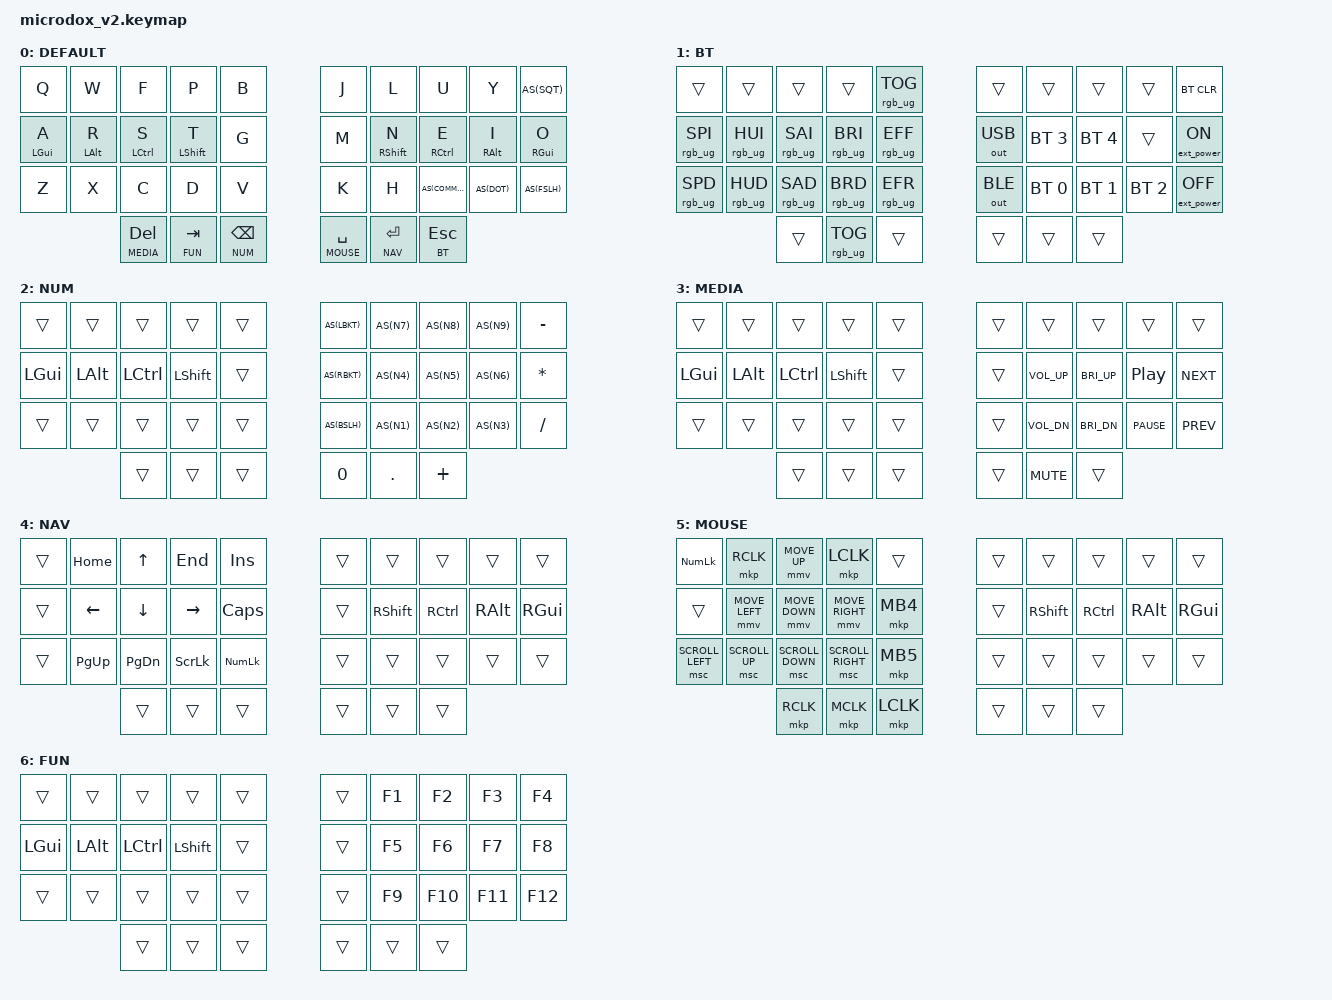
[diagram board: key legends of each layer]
/*
 * Copyright (c) 2020 The ZMK Contributors
 *
 * SPDX-License-Identifier: MIT
 */

#include <behaviors.dtsi>
#include <dt-bindings/zmk/keys.h>
#include <dt-bindings/zmk/bt.h>
#include <dt-bindings/zmk/outputs.h>
#include <dt-bindings/zmk/ext_power.h>
#include <dt-bindings/zmk/rgb.h>
#include <dt-bindings/zmk/mouse.h>

#define DEFAULT 0
#define BT      1
#define NUM     2
#define MEDIA   3
#define NAV     4
#define MOUSE   5
#define FUN     6

#define AS(keycode) &as LS(keycode) keycode

&lt { quick_tap_ms = <140>; };

&sk {
    release-after-ms = <1000>;
    quick-release;
    /delete-property/ ignore-modifiers;
};
/ {
    macros {
         ZMK_MACRO(macro_email,
            wait-ms = <20>;
            tap-ms = <20>;
            bindings
                = <&macro_tap &kp C &kp H &kp E &kp U &kp N &kp G &kp DOT &kp E &kp D &kp E &kp N &kp DOT &kp L &kp A &kp W>
                , <&macro_press &kp LSHFT>
                , <&macro_tap &kp N2>
                , <&macro_release &kp LSHFT>
                , <&macro_tap &kp G &kp M &kp A &kp I &kp L &kp DOT &kp C &kp O &kp M>
                ;
        )
    };
};

/{
    combos {
        compatible = "zmk,combos";
        combo_min {
            timeout-ms = <25>;
            key-positions = <3 13>;
            bindings = <&kp MINUS>;
        };
        
        combo_gresc {
            timeout-ms = <25>;
            key-positions = <23 24>;
            bindings = <&kp ESC>;
        };
        
        combo_caps {
            timeout-ms = <25>;
            key-positions = <13 14>;
            bindings = <&caps_word>;
        }; 
        
        combo_lpar {
            timeout-ms = <25>;
            key-positions = <3 4>;
            bindings = <&kp LPAR>;
        };
       
        combo_eql {
            timeout-ms = <25>;
            key-positions = <6 16>;
            bindings = <&kp EQUAL>;
        };
        
        combo_semi {
            timeout-ms = <20>;
            key-positions = <15 16>;
            bindings = <&kp SEMI>;
        }; 
        
        combo_rpar {
            timeout-ms = <25>;
            key-positions = <5 6>;
            bindings = <&kp RPAR>;
        };
        
        combo_print {
            timeout-ms = <25>;
            key-positions = <0 9>;
            bindings = <&kp PSCRN>;
        };        
 
         combo_play {
            timeout-ms = <25>;
            key-positions = <0 20>;
            bindings = <&kp C_PP>;
        };
        
        combo_mute {
            timeout-ms = <25>;
            key-positions = <9 29>;
            bindings = <&kp C_MUTE>;
        };     
        
        combo_del {
            timeout-ms = <25>;
            key-positions = <31 32>;
            bindings = <&kp DEL>;
        };
        
        combo_grescr {
            timeout-ms = <25>;
            key-positions = <33 34>;
            bindings = <&gresc>;
        };  
        combo_email {
            timeout-ms = <25>;
            key-positions = <25 26>;
            bindings = <&macro_email>;
        };

    };
};

/{
    behaviors {
        hm: homerow_mods {
            compatible = "zmk,behavior-hold-tap";
            label = "HOMEROW_MODS";
            #binding-cells = <2>;
            tapping-term-ms = <180>; // <---[[produces tap if held longer than tapping-term-ms]]
            quick-tap-ms = <140>;
            flavor = "tap-preferred";
            bindings = <&kp>, <&kp>;
        };
        
       as: auto_shift {
            compatible = "zmk,behavior-hold-tap";
            label = "AUTO_SHIFT";
            #binding-cells = <2>;
            tapping_term_ms = <180>;
            quick_tap_ms = <0>;
            flavor = "tap-preferred";
            bindings = <&kp>, <&kp>;
        };  
        
     gresc: grave_escape {
            compatible = "zmk,behavior-mod-morph";
            label = "GRAVE_ESCAPE";
            #binding-cells = <0>;
            bindings = <&kp ESC>, <&kp GRAVE>;
            mods = <(MOD_LGUI|MOD_LSFT|MOD_RGUI|MOD_RSFT)>;
        };   
    }; 
};

&mmv {
    time-to-max-speed-ms = <300>;
};

&mwh {
    acceleration-exponent=<0>;
};

/{
    keymap {
        compatible = "zmk,keymap";

                      DEFAULT {
// -----------------------------------------------------------------------------------------
//                              |  Q  |  W  |  F  |  P  |  B  |   |  J  |  L   |  U  |  Y  |  '  | 
//                              |  A  |  R  |  S  |  T  |  G  |   |  M  |  N   |  E  |  I  |  O  |
//                              |  Z  |  X  |  C  |  D  |  V  |   |  K  |  H   |  ,  |  .  |  /  | 
//                                          | DEL | TAB | BSP |   | SPC  | ENT | ESC |
                        bindings = <
  &kp Q      &kp W      &kp F         &kp P        &kp B         &kp J      &kp L            &kp U       &kp Y       AS(SQT)    
  &hm LGUI A &hm LALT R &hm LCTRL S   &hm LSHIFT T &kp G         &kp M      &hm RSHIFT N     &hm RCTRL E &hm RALT I  &hm RGUI O 
  &kp Z      &kp X      &kp C         &kp D        &kp V         &kp K      &kp H            AS(COMMA)   AS(DOT)     AS(FSLH)   
                     &lt MEDIA DEL  &lt FUN TAB &lt NUM BSPC  &lt MOUSE SPACE &lt NAV RET  &lt BT ESC
                        >;
                
                sensor-bindings = <&inc_dec_kp C_VOL_DN C_VOL_UP &inc_dec_kp PG_UP PG_DN>; 
                        
                };
                BT {
// -----------------------------------------------------------------------------------------
//                         |      |     |     |     |     |     |   |     |     |     |     | BTCR |
//                         | EPON |     |     |     |     |     |   |USBPR| BT4 | BT5 |     | EPON |
//                         | EPOFF|     |     |     |     |     |   |BT PR| BT1 | BT2 | BT3 | EPOFF|
//                                            |     |     |     |   |     |     |     |     
                        bindings = <
   &trans          &trans          &trans          &trans          &rgb_ug RGB_TOG    &trans        &trans        &trans       &trans        &bt BT_CLR
   &rgb_ug RGB_SPI &rgb_ug RGB_HUI &rgb_ug RGB_SAI &rgb_ug RGB_BRI &rgb_ug RGB_EFF    &out OUT_USB  &bt BT_SEL 3  &bt BT_SEL 4 &trans        &ext_power EP_ON
   &rgb_ug RGB_SPD &rgb_ug RGB_HUD &rgb_ug RGB_SAD &rgb_ug RGB_BRD &rgb_ug RGB_EFR    &out OUT_BLE  &bt BT_SEL 0  &bt BT_SEL 1 &bt BT_SEL 2  &ext_power EP_OFF
                         &trans     &rgb_ug RGB_TOG &trans             &trans        &trans        &trans
                        >;
                };

                NUM {
// -----------------------------------------------------------------------------------------
//                       |     |     |     |     |     |   |  [  |  7  |  8  |  9  |  -  | 
//                       | GUI | ALT | CTL | SFT |     |   |  ]  |  4  |  5  |  6  |  *  | 
//                       |     |     |     |     |     |   |  \  |  1  |  2  |  3  |  /  | 
//                                   |     |     |     |   |  +  |  0  |  .  |     
                        bindings = <
  &trans     &trans     &trans     &trans     &trans         AS(LBKT)   AS(N7)  AS(N8) AS(N9) &kp MINUS 
  &kp LGUI   &kp LALT   &kp LCTRL  &kp LSHFT  &trans         AS(RBKT)   AS(N4)  AS(N5) AS(N6) &kp STAR  
  &trans     &trans     &trans     &trans     &trans         AS(BSLH)   AS(N1)  AS(N2) AS(N3) &kp FSLH 
                        &trans     &trans     &trans         &kp N0     &kp DOT &kp PLUS   
                        >;
                        
                        sensor-bindings = <&inc_dec_kp C_VOL_DN C_VOL_UP>; 
                };
                
                MEDIA {
// -----------------------------------------------------------------------------------------
//                     |     |     |     |     |     |   |     |     |     |     |     |
//                     | GUI | ALT | CTL | SFT |     |   |     | VUP | BUP | PLY | NXT | 
//                     |     |     |     |     |     |   |     | VDN | BDN | PSE | PRV |
//                                 |     |     |     |   |     |     | MUTE|     |
                        bindings = <
    &trans     &trans     &trans     &trans     &trans         &trans   &trans       &trans       &trans      &trans     
    &kp LGUI   &kp LALT   &kp LCTRL  &kp LSHFT  &trans         &trans   &kp C_VOL_UP &kp C_BRI_UP &kp C_PP    &kp C_NEXT 
    &trans     &trans     &trans     &trans     &trans         &trans   &kp C_VOL_DN &kp C_BRI_DN &kp C_PAUSE &kp C_PREV 
                   	      &trans     &trans     &trans         &trans   &kp C_MUTE   &trans
                        >;
                };
                
                NAV {
// -----------------------------------------------------------------------------------------
//                           |     | HOME|  UP | END | INS |   |     |     |     |     |     |  
//                           |     | LEFT| DOWN|RIGHT| CAPS|   |     | SFT | CTL | ALT | GUI |   
//                           |     | PGUP| PGDN| SLCK| NUML|   |     |     |     |     |     | 
//                                       |     |     |     |   |     |     |     |     
                        bindings = <
   &trans    &kp HOME   &kp UP     &kp END    &kp INS        &trans   &trans     &trans     &trans     &trans    
   &trans    &kp LEFT   &kp DOWN   &kp RIGHT  &kp CAPS       &trans   &kp RSHFT  &kp RCTRL  &kp RALT   &kp RGUI 
   &trans    &kp PG_UP  &kp PG_DN  &kp SLCK   &kp KP_NUM     &trans   &trans     &trans     &trans     &trans   
                        &trans     &trans     &trans         &trans   &trans     &trans
                        >;
                        
                        sensor-bindings = <&inc_dec_kp LC(LS(TAB)) LC(TAB)>; 
                };
                
                MOUSE {
// -----------------------------------------------------------------------------------------
//                        | NUML |     | MU  |     |     |     |   |     |     |     |     |     |      |
//                        |      | ML  | MD  | MR  |     |     |   |     | SFT | CTL | ALT | GUI |      |
//                        |      |     |     |     |     |     |   |     |     |     |     |     |      |
//                                           | M2  | M1  | M3  |   |     |     |     |     |
                        bindings = <
   &kp KP_NUM       &mkp RCLK      &mmv MOVE_UP     &mkp LCLK         &trans         &trans   &trans     &trans     &trans     &trans     
   &trans           &mmv MOVE_LEFT &mmv MOVE_DOWN   &mmv MOVE_RIGHT   &mkp MB4       &trans   &kp RSHFT  &kp RCTRL  &kp RALT   &kp RGUI   
   &msc SCROLL_LEFT &msc SCROLL_UP &msc SCROLL_DOWN &msc SCROLL_RIGHT &mkp MB5       &trans   &trans     &trans     &trans     &trans     
                                   &mkp RCLK        &mkp MCLK         &mkp LCLK      &trans   &trans     &trans
                        >;
                        
                        sensor-bindings = <&inc_dec_kp PG_UP PG_DN>;
                };
                
                FUN {
// -----------------------------------------------------------------------------------------
//                     |     |     |     |     |     |   |     |  F1 |  F2 |  F3 |  F4 |
//                     | GUI | ALT | CTL | SFT |     |   |     |  F5 |  F6 |  F7 |  F8 | 
//                     |     |     |     |     |     |   |     |  F9 | F10 | F11 | F12 |
//                                 |     |     |     |   |     |     |     |     |
                        bindings = <
     &trans     &trans     &trans     &trans     &trans         &trans   &kp F1  &kp F2  &kp F3  &kp F4   
     &kp LGUI   &kp LALT   &kp LCTRL  &kp LSHFT  &trans         &trans   &kp F5  &kp F6  &kp F7  &kp F8   
     &trans     &trans     &trans     &trans     &trans         &trans   &kp F9  &kp F10 &kp F11 &kp F12 
                           &trans     &trans     &trans         &trans   &trans  &trans
                        >;
                };
        };
};
